AUTOSAR XML (schema 00046)
package /ComponentTypes
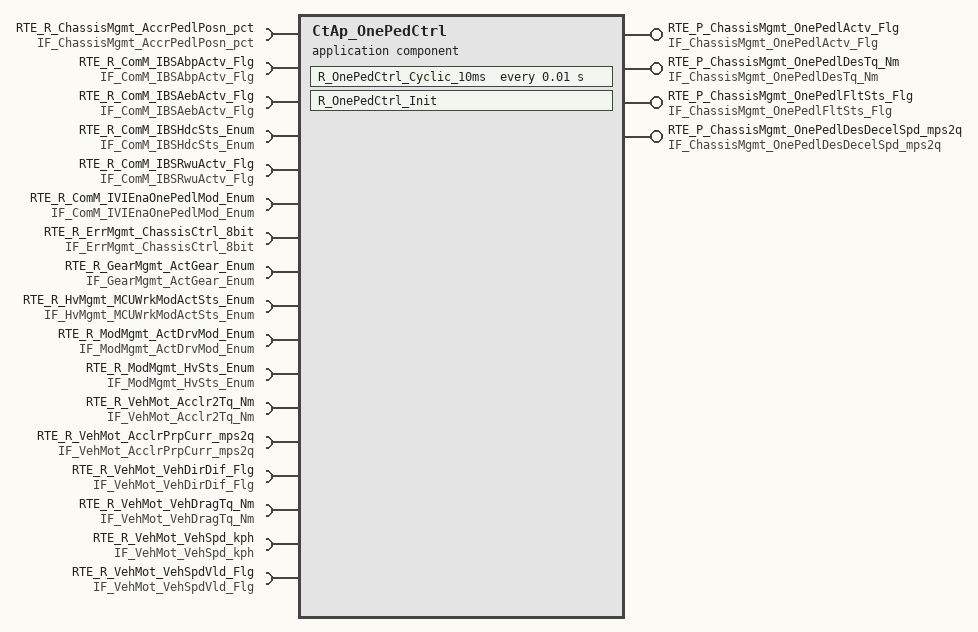
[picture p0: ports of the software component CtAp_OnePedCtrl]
  application sw component type CtAp_OnePedCtrl
    4 x provide port:
      RTE_P_ChassisMgmt_OnePedlActv_Flg: nonqueued-sender-com-spec{data-element=tec_ChassisMgmt_OnePedlActv_Flg, init-value=0}, provided-interface=IF_ChassisMgmt_OnePedlActv_Flg
      RTE_P_ChassisMgmt_OnePedlDesTq_Nm: nonqueued-sender-com-spec{data-element=tec_ChassisMgmt_OnePedlDesTq_Nm, init-value=0}, provided-interface=IF_ChassisMgmt_OnePedlDesTq_Nm
      RTE_P_ChassisMgmt_OnePedlFltSts_Flg: nonqueued-sender-com-spec{data-element=tec_ChassisMgmt_OnePedlFltSts_Flg, init-value=0}, provided-interface=IF_ChassisMgmt_OnePedlFltSts_Flg
      RTE_P_ChassisMgmt_OnePedlDesDecelSpd_mps2q: nonqueued-sender-com-spec{data-element=tec_ChassisMgmt_OnePedlDesDecelSpd_mps2q, init-value=0}, provided-interface=IF_ChassisMgmt_OnePedlDesDecelSpd_mps2q
    17 x require port:
      RTE_R_ChassisMgmt_AccrPedlPosn_pct: nonqueued-receiver-com-spec{data-element=tec_ChassisMgmt_AccrPedlPosn_pct, filter=data-filter-type=ALWAYS, init-value=0}, required-interface=IF_ChassisMgmt_AccrPedlPosn_pct
      RTE_R_ComM_IBSAbpActv_Flg: nonqueued-receiver-com-spec{data-element=tec_ComM_IBSAbpActv_Flg, filter=data-filter-type=ALWAYS, init-value=0}, required-interface=IF_ComM_IBSAbpActv_Flg
      RTE_R_ComM_IBSAebActv_Flg: nonqueued-receiver-com-spec{data-element=tec_ComM_IBSAebActv_Flg, filter=data-filter-type=ALWAYS, init-value=0}, required-interface=IF_ComM_IBSAebActv_Flg
      RTE_R_ComM_IBSHdcSts_Enum: nonqueued-receiver-com-spec{data-element=tec_ComM_IBSHdcSts_Enum, filter=data-filter-type=ALWAYS, init-value=0}, required-interface=IF_ComM_IBSHdcSts_Enum
      RTE_R_ComM_IBSRwuActv_Flg: nonqueued-receiver-com-spec{data-element=tec_ComM_IBSRwuActv_Flg, filter=data-filter-type=ALWAYS, init-value=0}, required-interface=IF_ComM_IBSRwuActv_Flg
      RTE_R_ComM_IVIEnaOnePedlMod_Enum: nonqueued-receiver-com-spec{data-element=tec_ComM_IVIEnaOnePedlMod_Enum, filter=data-filter-type=ALWAYS, init-value=0}, required-interface=IF_ComM_IVIEnaOnePedlMod_Enum
      RTE_R_ErrMgmt_ChassisCtrl_8bit: nonqueued-receiver-com-spec{data-element=tec_ErrMgmt_ChassisCtrl_8bit, filter=data-filter-type=ALWAYS, init-value=0}, required-interface=IF_ErrMgmt_ChassisCtrl_8bit
      RTE_R_GearMgmt_ActGear_Enum: nonqueued-receiver-com-spec{data-element=tec_GearMgmt_ActGear_Enum, filter=data-filter-type=ALWAYS, init-value=0}, required-interface=IF_GearMgmt_ActGear_Enum
      RTE_R_HvMgmt_MCUWrkModActSts_Enum: nonqueued-receiver-com-spec{data-element=tec_HvMgmt_MCUWrkModActSts_Enum, filter=data-filter-type=ALWAYS, init-value=0}, required-interface=IF_HvMgmt_MCUWrkModActSts_Enum
      RTE_R_ModMgmt_ActDrvMod_Enum: nonqueued-receiver-com-spec{data-element=tec_ModMgmt_ActDrvMod_Enum, filter=data-filter-type=ALWAYS, init-value=0}, required-interface=IF_ModMgmt_ActDrvMod_Enum
      RTE_R_ModMgmt_HvSts_Enum: nonqueued-receiver-com-spec{data-element=tec_ModMgmt_HvSts_Enum, filter=data-filter-type=ALWAYS, init-value=0}, required-interface=IF_ModMgmt_HvSts_Enum
      RTE_R_VehMot_Acclr2Tq_Nm: nonqueued-receiver-com-spec{data-element=tec_VehMot_Acclr2Tq_Nm, filter=data-filter-type=ALWAYS, init-value=0}, required-interface=IF_VehMot_Acclr2Tq_Nm
      RTE_R_VehMot_AcclrPrpCurr_mps2q: nonqueued-receiver-com-spec{data-element=tec_VehMot_AcclrPrpCurr_mps2q, filter=data-filter-type=ALWAYS, init-value=0}, required-interface=IF_VehMot_AcclrPrpCurr_mps2q
      RTE_R_VehMot_VehDirDif_Flg: nonqueued-receiver-com-spec{data-element=tec_VehMot_VehDirDif_Flg, filter=data-filter-type=ALWAYS, init-value=0}, required-interface=IF_VehMot_VehDirDif_Flg
      RTE_R_VehMot_VehDragTq_Nm: nonqueued-receiver-com-spec{data-element=tec_VehMot_VehDragTq_Nm, filter=data-filter-type=ALWAYS, init-value=0}, required-interface=IF_VehMot_VehDragTq_Nm
      RTE_R_VehMot_VehSpd_kph: nonqueued-receiver-com-spec{data-element=tec_VehMot_VehSpd_kph, filter=data-filter-type=ALWAYS, init-value=0}, required-interface=IF_VehMot_VehSpd_kph
      RTE_R_VehMot_VehSpdVld_Flg: nonqueued-receiver-com-spec{data-element=tec_VehMot_VehSpdVld_Flg, filter=data-filter-type=ALWAYS, init-value=0}, required-interface=IF_VehMot_VehSpdVld_Flg
    behavior CtAp_OnePedCtrl_InternalBehavior
      init event CtAp_OnePedCtrl_InitEvent: start-on-event=R_OnePedCtrl_Init
      timing event TMT_R_OnePedCtrl_Cyclic_10ms: start-on-event=R_OnePedCtrl_Cyclic_10ms, period=0.01
      runnable R_OnePedCtrl_Init
      runnable R_OnePedCtrl_Cyclic_10ms
        data-receive-point-by-arguments:
          17 x access:
            REC_RTE_R_ChassisMgmt_AccrPedlPosn_pct_tec_ChassisMgmt_AccrPedlPosn_pct: accessed-variable=RTE_R_ChassisMgmt_AccrPedlPosn_pct.tec_ChassisMgmt_AccrPedlPosn_pct
            REC_RTE_R_ComM_IBSAbpActv_Flg_tec_ComM_IBSAbpActv_Flg: accessed-variable=RTE_R_ComM_IBSAbpActv_Flg.tec_ComM_IBSAbpActv_Flg
            REC_RTE_R_ComM_IBSAebActv_Flg_tec_ComM_IBSAebActv_Flg: accessed-variable=RTE_R_ComM_IBSAebActv_Flg.tec_ComM_IBSAebActv_Flg
            REC_RTE_R_ComM_IBSHdcSts_Enum_tec_ComM_IBSHdcSts_Enum: accessed-variable=RTE_R_ComM_IBSHdcSts_Enum.tec_ComM_IBSHdcSts_Enum
            REC_RTE_R_ComM_IBSRwuActv_Flg_tec_ComM_IBSRwuActv_Flg: accessed-variable=RTE_R_ComM_IBSRwuActv_Flg.tec_ComM_IBSRwuActv_Flg
            REC_RTE_R_Comm_IVIEnaOnePedlMod_Enum_tec_ComM_IVIEnaOnePedlMod_Enum: accessed-variable=RTE_R_ComM_IVIEnaOnePedlMod_Enum.tec_ComM_IVIEnaOnePedlMod_Enum
            REC_RTE_R_ErrMgmt_ChassisCtrl_8bit_tec_ErrMgmt_ChassisCtrl_8bit: accessed-variable=RTE_R_ErrMgmt_ChassisCtrl_8bit.tec_ErrMgmt_ChassisCtrl_8bit
            REC_RTE_R_GearMgmt_ActGear_Enum_tec_GearMgmt_ActGear_Enum: accessed-variable=RTE_R_GearMgmt_ActGear_Enum.tec_GearMgmt_ActGear_Enum
            REC_RTE_R_HvMgmt_MCUWrkModActSts_Enum_tec_HvMgmt_MCUWrkModActSts_Enum: accessed-variable=RTE_R_HvMgmt_MCUWrkModActSts_Enum.tec_HvMgmt_MCUWrkModActSts_Enum
            REC_RTE_R_ModMgmt_ActDrvMod_Enum_tec_ModMgmt_ActDrvMod_Enum: accessed-variable=RTE_R_ModMgmt_ActDrvMod_Enum.tec_ModMgmt_ActDrvMod_Enum
            REC_RTE_R_ModMgmt_HvSts_Enum_tec_ModMgmt_HvSts_Enum: accessed-variable=RTE_R_ModMgmt_HvSts_Enum.tec_ModMgmt_HvSts_Enum
            REC_RTE_R_VehMot_Acclr2Tq_Nm_tec_VehMot_Acclr2Tq_Nm: accessed-variable=RTE_R_VehMot_Acclr2Tq_Nm.tec_VehMot_Acclr2Tq_Nm
            REC_RTE_R_VehMot_AcclrPrpCurr_mps2q_tec_VehMot_AcclrPrpCurr_mps2q: accessed-variable=RTE_R_VehMot_AcclrPrpCurr_mps2q.tec_VehMot_AcclrPrpCurr_mps2q
            REC_RTE_R_VehMot_VehDirDif_Flg_tec_VehMot_VehDirDif_Flg: accessed-variable=RTE_R_VehMot_VehDirDif_Flg.tec_VehMot_VehDirDif_Flg
            REC_RTE_R_VehMot_VehDragTq_Nm_tec_VehMot_VehDragTq_Nm: accessed-variable=RTE_R_VehMot_VehDragTq_Nm.tec_VehMot_VehDragTq_Nm
            REC_RTE_R_VehMot_VehSpdVld_Flg_tec_VehMot_VehSpdVld_Flg: accessed-variable=RTE_R_VehMot_VehSpdVld_Flg.tec_VehMot_VehSpdVld_Flg
            REC_RTE_R_VehMot_VehSpd_kph_tec_VehMot_VehSpd_kph: accessed-variable=RTE_R_VehMot_VehSpd_kph.tec_VehMot_VehSpd_kph
        data-send-points:
          4 x access:
            SEND_RTE_P_ChassisMgmt_OnePedlActv_Flg_tec_ChassisMgmt_OnePedlActv_Flg: accessed-variable=RTE_P_ChassisMgmt_OnePedlActv_Flg.tec_ChassisMgmt_OnePedlActv_Flg
            SEND_RTE_P_ChassisMgmt_OnePedlDesDecelSpd_mps2q_tec_ChassisMgmt_OnePedlDesDecelSpd_mps2q: accessed-variable=RTE_P_ChassisMgmt_OnePedlDesDecelSpd_mps2q.tec_ChassisMgmt_OnePedlDesDecelSpd_mps2q
            SEND_RTE_P_ChassisMgmt_OnePedlDesTq_Nm_tec_ChassisMgmt_OnePedlDesTq_Nm: accessed-variable=RTE_P_ChassisMgmt_OnePedlDesTq_Nm.tec_ChassisMgmt_OnePedlDesTq_Nm
            SEND_RTE_P_ChassisMgmt_OnePedlFltSts_Flg_tec_ChassisMgmt_OnePedlFltSts_Flg: accessed-variable=RTE_P_ChassisMgmt_OnePedlFltSts_Flg.tec_ChassisMgmt_OnePedlFltSts_Flg
  swc implementation CtAp_OnePedCtrl_Implementation: behavior=CtAp_OnePedCtrl_InternalBehavior
    code-descriptors:
      code Default: artifact-descriptors=autosar-engineering-object=category=SWOBJ
